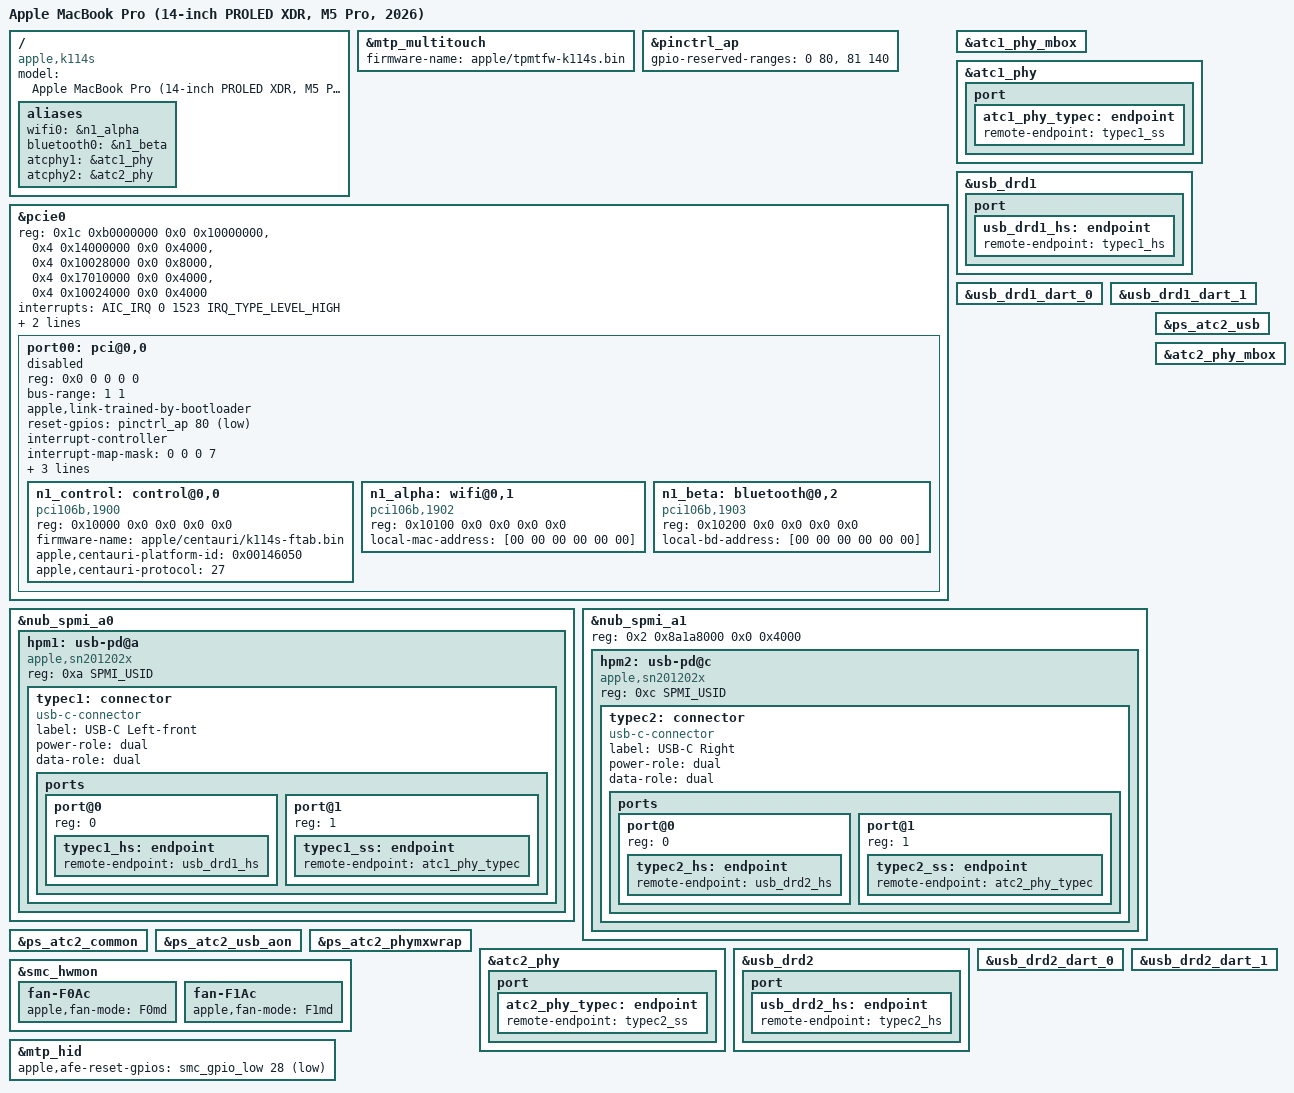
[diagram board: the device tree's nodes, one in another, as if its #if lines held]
// SPDX-License-Identifier: GPL-2.0+ OR MIT
/*
 * MacBook Pro (14-inch PROLED XDR, M5 Pro, 2026)
 *
 * target-type: K114s (Mac17,13), ADT /chosen board-id 0x14, chip 0x6050
 *
 * K114s repair r1 (experimental). The base is the preliminary tree that booted on a K114s on
 * 2026-11-13 (aurora-silicon/linux a34d26c2 t6050-k114s.dts plus the host iommu-map of
 * b0d53446). The sections below are taken from the K116s tree of aurora-silicon/linux #1648
 * (cd2c9f52, Jens Axboe, booted on a K116s) and from this base's J714s tree, where the 27.2
 * (26B8125) ADTs of the K114s and the K116s are identical node for node: same paths, pins,
 * addresses, interrupts and stream IDs. Only the board's own identity differs: the N1 platform
 * ID is this board's (0x14 << 16 | 0x6050) and the firmware names are k114s.
 *
 * K114S_R1_N1:   PCIe port 0 and the N1 (Wi-Fi, Bluetooth)
 * K114S_R1_USB:  the left-front and right USB-C ports (USB host), SMC sensors
 * K114S_R1_AFE_GP1C: trackpad AFE reset through SMC GPIO gp1c (K116s/J714s form)
 *
 * Copyright The Asahi Linux Contributors
 */

#include "t6050-k114-k116.dtsi"

/ {
	compatible = "apple,k114s", "apple,t6050", "apple,arm-platform";
	model = "Apple MacBook Pro (14-inch PROLED XDR, M5 Pro, 2026)";
};

&mtp_multitouch {
	firmware-name = "apple/tpmtfw-k114s.bin";
};

#define T6050_K114S
#include "t6050-peripherals.dtsi"

#ifdef K114S_R1_N1
/ {
	aliases {
		/* The loader fills the N1's factory addresses through these */
		wifi0 = &n1_alpha;
		bluetooth0 = &n1_beta;
	};
};

&pinctrl_ap {
	/*
	 * Only PCIe port 0's PERST#, pin 80 (ADT pci-bridge0 function-perst, gpio0 0x50), is
	 * exposed. The controller has 221 pins (ADT gpio0 #gpio-pins 0xdd), so the second range is
	 * 81..220: 140 pins, as in this base's t6050-j716c.dts. A range that runs past the last pin
	 * is skipped by gpiolib, which would expose pin 112, whose register takes an SError when
	 * read (aurora-silicon/linux b0d53446 wrote <81 141>; the final #1648 tree does not).
	 */
	gpio-reserved-ranges = <0 80>, <81 140>;
};

/*
 * PCIe port 0: the N1 (Wi-Fi and Bluetooth), laid out as on J714s and K116s. This board's ADT
 * apcie0 gives port 0's registers (reg[16], reg[18], reg[19]) and IRQ 1523 (0x5f3),
 * pci-bridge0's PERST# is gpio0 pin 80, and the N1's three functions are on DART streams 1-3.
 * The platform ID is this board's ADT /chosen board-id (0x14) << 16 | chip 0x6050.
 */
&pcie0 {
	reg = <0x1c 0xb0000000 0x0 0x10000000>,
	      <0x4 0x14000000 0x0 0x4000>,
	      <0x4 0x10028000 0x0 0x8000>,
	      <0x4 0x17010000 0x0 0x4000>,
	      <0x4 0x10024000 0x0 0x4000>;
	reg-names = "config", "rc", "port0", "phy0", "intr2axi0";
	interrupts = <AIC_IRQ 0 1523 IRQ_TYPE_LEVEL_HIGH>;
	interrupt-names = "port0";
	iommu-map = <0x100 &dart_apcie0 1 3>;
	bus-range = <0 4>;
	status = "okay";

	port00: pci@0,0 {
		device_type = "pci";
		reg = <0x0 0 0 0 0>;
		bus-range = <1 1>;
		apple,link-trained-by-bootloader;
		/* PERST#: ADT pci-bridge0 function-perst, GPIO 80 */
		reset-gpios = <&pinctrl_ap 80 GPIO_ACTIVE_LOW>;
		status = "disabled";

		#address-cells = <3>;
		#size-cells = <2>;
		ranges;

		interrupt-controller;
		#interrupt-cells = <1>;
		interrupt-map-mask = <0 0 0 7>;
		interrupt-map = <0 0 0 1 &port00 0 0 0 0>,
				<0 0 0 2 &port00 0 0 0 1>,
				<0 0 0 3 &port00 0 0 0 2>,
				<0 0 0 4 &port00 0 0 0 3>;

		n1_control: control@0,0 {
			compatible = "pci106b,1900";
			reg = <0x10000 0x0 0x0 0x0 0x0>;
			firmware-name = "apple/centauri/k114s-ftab.bin";
			apple,centauri-platform-id = <0x00146050>;
			apple,centauri-protocol = <27>;
		};

		n1_alpha: wifi@0,1 {
			compatible = "pci106b,1902";
			reg = <0x10100 0x0 0x0 0x0 0x0>;
			local-mac-address = [00 00 00 00 00 00];
		};

		n1_beta: bluetooth@0,2 {
			compatible = "pci106b,1903";
			reg = <0x10200 0x0 0x0 0x0 0x0>;
			local-bd-address = [00 00 00 00 00 00];
		};
	};
};
#else
/* As the tree that booted: the host stays disabled and carries what aura's hand-off reads */
&pcie0 {
	iommu-map = <0x100 &dart_apcie0 1 3>;
	bus-range = <0 4>;
	status = "disabled";
};
#endif

#ifdef K114S_R1_USB
/*
 * Type-C, from the ADT (as on K116s and J714s):
 *   ATC0 usb-drd0 left-back  hpm0 nub-spmi-a0 0x0c (the debug port, not described)
 *   ATC1 usb-drd1 left-front hpm1 nub-spmi-a0 0x0a
 *   ATC2 usb-drd2 right      hpm2 nub-spmi-a1 0x0c
 *   hpm5 nub-spmi-a0 0x08 (MagSafe, not a USB-C connector)
 */

/ {
	aliases {
		/* The loader fills the PHYs' tunables from the ADT through these */
		atcphy1 = &atc1_phy;
		atcphy2 = &atc2_phy;
	};
};

/* Left-front port (ATC1): the SN201202x hpm1 and the connector graph */
&nub_spmi_a0 {
	status = "okay";

	hpm1: usb-pd@a {
		compatible = "apple,sn201202x";
		reg = <0xa SPMI_USID>;

		typec1: connector {
			compatible = "usb-c-connector";
			label = "USB-C Left-front";
			power-role = "dual";
			data-role = "dual";

			ports {
				#address-cells = <1>;
				#size-cells = <0>;

				port@0 {
					reg = <0>;

					typec1_hs: endpoint {
						remote-endpoint = <&usb_drd1_hs>;
					};
				};

				port@1 {
					reg = <1>;

					typec1_ss: endpoint {
						remote-endpoint = <&atc1_phy_typec>;
					};
				};
			};
		};
	};
};

&atc1_phy_mbox {
	status = "okay";
};

&atc1_phy {
	status = "okay";

	port {
		atc1_phy_typec: endpoint {
			remote-endpoint = <&typec1_ss>;
		};
	};
};

&usb_drd1 {
	status = "okay";

	port {
		usb_drd1_hs: endpoint {
			remote-endpoint = <&typec1_hs>;
		};
	};
};

&usb_drd1_dart_0 {
	status = "okay";
};

&usb_drd1_dart_1 {
	status = "okay";
};

/*
 * Right port (ATC2): hpm2 on nub-spmi-a1, USB only. The driver polls the generation 4 bus and
 * refuses an interrupt, so it takes the first register window only, as on K116s and J714s.
 */
&nub_spmi_a1 {
	reg = <0x2 0x8a1a8000 0x0 0x4000>;
	/delete-property/ interrupts;
	status = "okay";

	hpm2: usb-pd@c {
		compatible = "apple,sn201202x";
		reg = <0xc SPMI_USID>;

		typec2: connector {
			compatible = "usb-c-connector";
			label = "USB-C Right";
			power-role = "dual";
			data-role = "dual";

			ports {
				#address-cells = <1>;
				#size-cells = <0>;

				port@0 {
					reg = <0>;

					typec2_hs: endpoint {
						remote-endpoint = <&usb_drd2_hs>;
					};
				};

				port@1 {
					reg = <1>;

					typec2_ss: endpoint {
						remote-endpoint = <&atc2_phy_typec>;
					};
				};
			};
		};
	};
};

&ps_atc2_common {
	status = "okay";
};

&ps_atc2_usb_aon {
	status = "okay";
};

&ps_atc2_phymxwrap {
	status = "okay";
};

&ps_atc2_usb {
	status = "okay";
};

&atc2_phy_mbox {
	status = "okay";
};

&atc2_phy {
	status = "okay";

	port {
		atc2_phy_typec: endpoint {
			remote-endpoint = <&typec2_ss>;
		};
	};
};

&usb_drd2 {
	status = "okay";

	port {
		usb_drd2_hs: endpoint {
			remote-endpoint = <&typec2_hs>;
		};
	};
};

&usb_drd2_dart_0 {
	status = "okay";
};

&usb_drd2_dart_1 {
	status = "okay";
};

/*
 * SMC sensors, as on K116s and J714s: every readable float T* key is discovered through
 * apple,discover-temperatures in t6050-die0.dtsi. The T6050 SMC spells the fan mode keys
 * F0md/F1md and drives the fans itself.
 */
#include "hwmon-common.dtsi"
#include "hwmon-fan-dual.dtsi"
#include "hwmon-laptop.dtsi"

&smc_hwmon {
	status = "okay";
	/delete-property/ apple,soc-die-keys;
	/delete-node/ temperature-TH0x;
	/delete-node/ temperature-TB0T;
	/delete-node/ temperature-TCHP;
	/delete-node/ temperature-TW0P;

	fan-F0Ac {
		apple,fan-mode = "F0md";
	};

	fan-F1Ac {
		apple,fan-mode = "F1md";
	};
};
#endif

#ifdef K114S_R1_AFE_GP1C
/*
 * Alternative trackpad AFE reset, as the K116s tree of aurora-silicon/linux #1648 (377b2a2d) and
 * this base's J714s tree drive it: the ADT names the SMC pcIO template (0x10000, 0x11c0000), the
 * same line as SMC GPIO gp1c, active low. On the K116s "through the pcIO outputs the multi-touch
 * interface never comes up". The K114s ADT's function-afe-reset is identical to the K116s's. The
 * default r1 tree keeps the pcIO form because the K114s enumerated its trackpad with it.
 */
&mtp_hid {
	apple,afe-reset-gpios = <&smc_gpio_low 28 GPIO_ACTIVE_LOW>;
};
#endif
